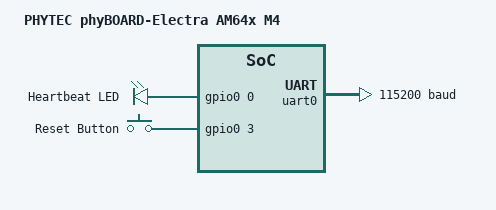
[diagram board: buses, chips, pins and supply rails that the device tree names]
/*
 * Copyright (C) 2024 PHYTEC Messtechnik GmbH
 * Author: Daniel Schultz <d.schultz@phytec.de>
 *
 * SPDX-License-Identifier: Apache-2.0
 */

/dts-v1/;

#include <elements/elemrv1.dtsi>

/ {
	model = "PHYTEC phyBOARD-Electra AM64x M4";
	compatible = "aesc,elemrv1";

	chosen {
		zephyr,console = &uart0;
		zephyr,shell-uart = &uart0;
		zephyr,sram = &ram0;
		zephyr,flash = &flash0;
	};

	aliases {
		led0 = &heartbeat_led;
	};

	leds: leds {
		compatible = "gpio-leds";
		heartbeat_led: led_0 {
			gpios = <&gpio0 0 GPIO_ACTIVE_HIGH>;
			label = "Heartbeat LED";
		};
	};
	keys {
		compatible = "gpio-keys";
		reset_btn: reset_btn {
			gpios = <&gpio0 3 GPIO_ACTIVE_HIGH>;
			label = "Reset Button";
		};
	};
};

&uart0 {
	current-speed = <115200>;
	status = "okay";
};

&gpio0 {
	status = "okay";
};
